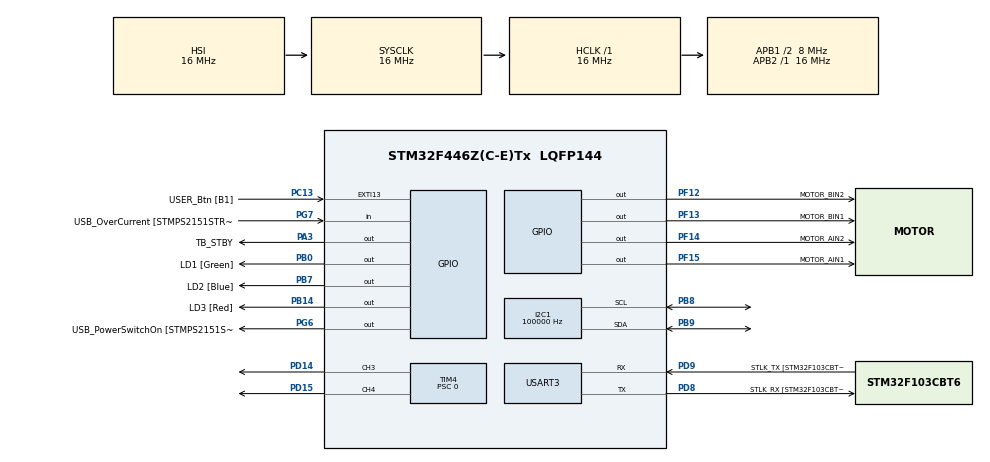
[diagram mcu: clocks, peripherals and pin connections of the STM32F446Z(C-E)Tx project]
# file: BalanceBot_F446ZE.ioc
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I2C1.Analog_Filter=I2C_ANALOGFILTER_ENABLE
I2C1.ClockSpeed=100000
I2C1.I2C_Coeff_DF=0
Mcu.Family=STM32F4
Mcu.Name=STM32F446Z(C-E)Tx
Mcu.Package=LQFP144
NVIC.PriorityGroup=NVIC_PRIORITYGROUP_4
NVIC.USART3_IRQn=true\:0\:0\:false\:false\:true\:true\:true\:true
PA10.GPIO_Label=USB_ID
PA10.Signal=USB_OTG_FS_ID
PA11.GPIO_Label=USB_DM
PA11.Signal=USB_OTG_FS_DM
PA12.GPIO_Label=USB_DP
PA12.Signal=USB_OTG_FS_DP
PA13.GPIO_Label=TMS
PA13.Mode=Serial_Wire
PA13.Signal=SYS_JTMS-SWDIO
PA14.GPIO_Label=TCK
PA14.Mode=Serial_Wire
PA14.Signal=SYS_JTCK-SWCLK
PA3.GPIO_Label=TB_STBY
PA3.Signal=GPIO_Output
PA8.GPIO_Label=USB_SOF [TP1]
PA8.Signal=USB_OTG_FS_SOF
PA9.GPIO_Label=USB_VBUS
PA9.Signal=USB_OTG_FS_VBUS
PB0.GPIO_Label=LD1 [Green]
PB0.Signal=GPIO_Output
PB14.GPIO_Label=LD3 [Red]
PB14.Signal=GPIO_Output
PB7.GPIO_Label=LD2 [Blue]
PB7.Signal=GPIO_Output
PB8.GPIO_PuPd=GPIO_PULLUP
PB8.Mode=I2C
PB8.Signal=I2C1_SCL
PB9.GPIO_PuPd=GPIO_PULLUP
PB9.Mode=I2C
PB9.Signal=I2C1_SDA
PC13.GPIO_Label=USER_Btn [B1]
PC13.Signal=GPXTI13
PC14-OSC32_IN.Signal=RCC_OSC32_IN
PC15-OSC32_OUT.Signal=RCC_OSC32_OUT
PD14.Signal=S_TIM4_CH3
PD15.Signal=S_TIM4_CH4
PD8.GPIO_Label=STLK_RX [STM32F103CBT6_PA3]
PD8.Mode=Asynchronous
PD8.Signal=USART3_TX
PD9.GPIO_Label=STLK_TX [STM32F103CBT6_PA2]
PD9.Mode=Asynchronous
PD9.Signal=USART3_RX
PF12.GPIO_Label=MOTOR_BIN2
PF12.Signal=GPIO_Output
PF13.GPIO_Label=MOTOR_BIN1
PF13.Signal=GPIO_Output
PF14.GPIO_Label=MOTOR_AIN2
PF14.Signal=GPIO_Output
PF15.GPIO_Label=MOTOR_AIN1
PF15.Signal=GPIO_Output
PG6.GPIO_Label=USB_PowerSwitchOn [STMPS2151STR_EN]
PG6.Signal=GPIO_Output
PG7.GPIO_Label=USB_OverCurrent [STMPS2151STR_FAULT]
PG7.Signal=GPIO_Input
PH0-OSC_IN.GPIO_Label=MCO [STM32F103CBT6_PA8]
PH0-OSC_IN.Signal=RCC_OSC_IN
PH1-OSC_OUT.Signal=RCC_OSC_OUT
ProjectManager.HeapSize=0x200
ProjectManager.StackSize=0x800
ProjectManager.TargetToolchain=STM32CubeIDE
RCC.48MHZClocksFreq_Value=24000000
RCC.AHBFreq_Value=16000000
RCC.APB1CLKDivider=RCC_HCLK_DIV2
RCC.APB1Freq_Value=8000000
RCC.APB1TimFreq_Value=16000000
RCC.APB2Freq_Value=16000000
RCC.APB2TimFreq_Value=16000000
RCC.CortexFreq_Value=16000000
RCC.HCLKFreq_Value=16000000
RCC.HSE_VALUE=8000000
RCC.HSI_VALUE=16000000
RCC.LSE_VALUE=32768
RCC.PLLMUL=RCC_PLL_MUL9
RCC.PRESCALERUSB=RCC_USBCLKSOURCE_PLL_DIV1_5
RCC.SYSCLKFreq_VALUE=16000000
RCC.SYSCLKSourceVirtual=RCC_SYSCLKSOURCE_PLLCLK
RCC.USBFreq_Value=96000000
RCC.VCOOutputFreq_Value=192000000
SH.S_TIM4_CH3.0=TIM4_CH3,PWM Generation3 CH3
SH.S_TIM4_CH4.0=TIM4_CH4,PWM Generation4 CH4
TIM4.Channel-PWM\ Generation3\ CH3=TIM_CHANNEL_3
TIM4.Channel-PWM\ Generation4\ CH4=TIM_CHANNEL_4
TIM4.Period=799
TIM4.Prescaler=0
USART3.VirtualMode=VM_ASYNC
VP_TIM4_VS_ClockSourceINT.Mode=Internal
board=NUCLEO-F446ZE

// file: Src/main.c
/* USER CODE BEGIN Header */
/**
  ******************************************************************************
  * @file           : main.c
  * @brief          : Main program body
  ******************************************************************************
  * @attention
  *
  * Copyright (c) 2026 STMicroelectronics.
  * All rights reserved.
  *
  * This software is licensed under terms that can be found in the LICENSE file
  * in the root directory of this software component.
  * If no LICENSE file comes with this software, it is provided AS-IS.
  *
  ******************************************************************************
  */
/* USER CODE END Header */
#include "main.h"
#include "i2c.h"
#include "tim.h"
#include "usart.h"
#include "gpio.h"

/* USER CODE BEGIN Includes */
#include "balance_bot.h"
/* USER CODE END Includes */

void SystemClock_Config(void);

int main(void)
{

  /* MCU Configuration--------------------------------------------------------*/

  /* Reset of all peripherals, Initializes the Flash interface and the Systick. */
  HAL_Init();

  /* Configure the system clock */
  SystemClock_Config();

  /* Initialize all configured peripherals */
  MX_GPIO_Init();
  MX_I2C1_Init();
  MX_TIM4_Init();
  MX_USART3_UART_Init();
  /* USER CODE BEGIN 2 */
  BalanceBot_Init();
  /* USER CODE END 2 */

  /* Infinite loop */
  while (1)
  {

    /* USER CODE BEGIN 3 */
    BalanceBot_Process();
  }
  /* USER CODE END 3 */
}

void SystemClock_Config(void)
{
  RCC_OscInitTypeDef RCC_OscInitStruct = {0};
  RCC_ClkInitTypeDef RCC_ClkInitStruct = {0};

  /** Configure the main internal regulator output voltage
  */
  __HAL_RCC_PWR_CLK_ENABLE();
  __HAL_PWR_VOLTAGESCALING_CONFIG(PWR_REGULATOR_VOLTAGE_SCALE3);

  /** Initializes the RCC Oscillators according to the specified parameters
  * in the RCC_OscInitTypeDef structure.
  */
  RCC_OscInitStruct.OscillatorType = RCC_OSCILLATORTYPE_HSI;
  RCC_OscInitStruct.HSIState = RCC_HSI_ON;
  RCC_OscInitStruct.HSICalibrationValue = RCC_HSICALIBRATION_DEFAULT;
  RCC_OscInitStruct.PLL.PLLState = RCC_PLL_NONE;
  if (HAL_RCC_OscConfig(&RCC_OscInitStruct) != HAL_OK)
  {
    Error_Handler();
  }

  /** Initializes the CPU, AHB and APB buses clocks
  */
  RCC_ClkInitStruct.ClockType = RCC_CLOCKTYPE_HCLK|RCC_CLOCKTYPE_SYSCLK
                              |RCC_CLOCKTYPE_PCLK1|RCC_CLOCKTYPE_PCLK2;
  RCC_ClkInitStruct.SYSCLKSource = RCC_SYSCLKSOURCE_HSI;
  RCC_ClkInitStruct.AHBCLKDivider = RCC_SYSCLK_DIV1;
  RCC_ClkInitStruct.APB1CLKDivider = RCC_HCLK_DIV2;
  RCC_ClkInitStruct.APB2CLKDivider = RCC_HCLK_DIV1;

  if (HAL_RCC_ClockConfig(&RCC_ClkInitStruct, FLASH_LATENCY_0) != HAL_OK)
  {
    Error_Handler();
  }
}

void Error_Handler(void)
{
  __disable_irq();
  while (1)
  {
  }
}
